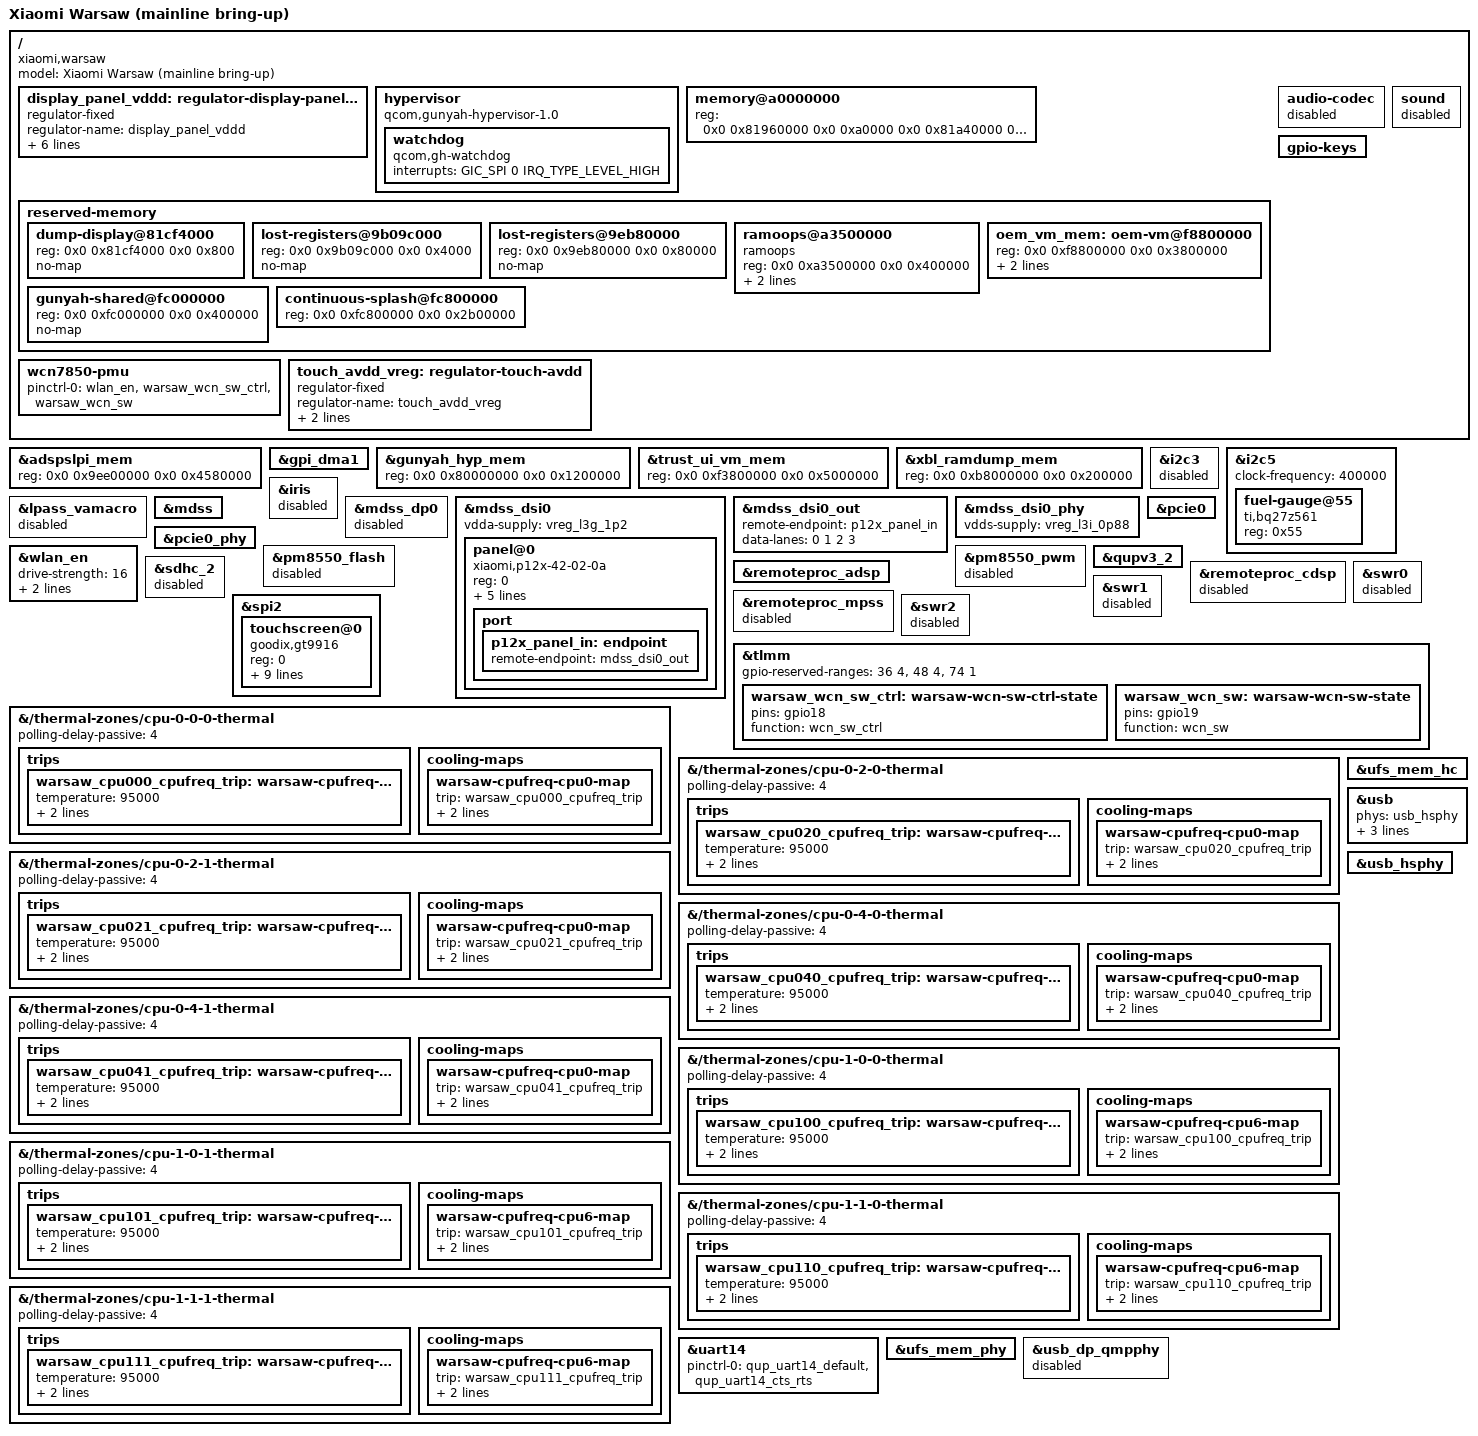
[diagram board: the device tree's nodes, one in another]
// SPDX-License-Identifier: BSD-3-Clause

#include "sm8750-mtp.dts"

/delete-node/ &cpusys_vm_mem;
/delete-node/ &oem_vm_mem;

/ {
	model = "Xiaomi Warsaw (mainline bring-up)";
	compatible = "xiaomi,warsaw", "qcom,sm8750";

	display_panel_vddd: regulator-display-panel-vddd {
		compatible = "regulator-fixed";
		regulator-name = "display_panel_vddd";
		regulator-min-microvolt = <1100000>;
		regulator-max-microvolt = <1100000>;
		gpio = <&tlmm 120 GPIO_ACTIVE_HIGH>;
		enable-active-high;
		regulator-always-on;
		regulator-boot-on;
	};

	hypervisor {
		compatible = "qcom,gunyah-hypervisor-1.0",
			     "qcom,gunyah-hypervisor", "simple-bus";
		#address-cells = <2>;
		#size-cells = <0>;

		watchdog {
			compatible = "qcom,gh-watchdog";
			interrupts = <GIC_SPI 0 IRQ_TYPE_LEVEL_HIGH>;
		};
	};

	memory@a0000000 {
		reg = <0x0 0x81960000 0x0 0xa0000
		       0x0 0x81a40000 0x0 0x1c0000
		       0x0 0x81cf4800 0x0 0xb800
		       0x0 0x82460000 0x0 0x40000
		       0x0 0xd8600000 0x0 0x0
		       0x0 0xe3720000 0x0 0x150e0000
		       0x0 0xfc400000 0x0 0x3400000
		       0x8 0x80000000 0x0 0x2f6fd000
		       0x8 0xb0000000 0x0 0x5500000
		       0xa 0x00000000 0x2 0x00000000
		       0x8 0xc0000000 0x1 0x40000000
		       0x8 0xb5700000 0x0 0x1e00000
		       0x0 0x82800000 0x0 0x2200000
		       0x0 0x89d80000 0x0 0x1c80000
		       0x0 0xa3380000 0x0 0x14c80000
		       0x0 0xb8200000 0x0 0x1cc23000
		       0x0 0xd5100000 0x0 0x2f00000>;
	};

	reserved-memory {
		dump-display@81cf4000 {
			reg = <0x0 0x81cf4000 0x0 0x800>;
			no-map;
		};

		lost-registers@9b09c000 {
			reg = <0x0 0x9b09c000 0x0 0x4000>;
			no-map;
		};

		lost-registers@9eb80000 {
			reg = <0x0 0x9eb80000 0x0 0x80000>;
			no-map;
		};

		ramoops@a3500000 {
			compatible = "ramoops";
			reg = <0x0 0xa3500000 0x0 0x400000>;
			console-size = <0x200000>;
			pmsg-size = <0x200000>;
		};

		oem_vm_mem: oem-vm@f8800000 {
			reg = <0x0 0xf8800000 0x0 0x3800000>;
			alignment = <0x0 0x400000>;
			no-map;
		};

		gunyah-shared@fc000000 {
			reg = <0x0 0xfc000000 0x0 0x400000>;
			no-map;
		};

		continuous-splash@fc800000 {
			reg = <0x0 0xfc800000 0x0 0x2b00000>;
		};
	};

	audio-codec {
		status = "disabled";
	};

	gpio-keys {
		status = "okay";
	};

	sound {
		status = "disabled";
	};

	wcn7850-pmu {
		pinctrl-0 = <&wlan_en>,
			    <&warsaw_wcn_sw_ctrl>,
			    <&warsaw_wcn_sw>;
	};

	touch_avdd_vreg: regulator-touch-avdd {
		compatible = "regulator-fixed";
		regulator-name = "touch_avdd_vreg";

		gpio = <&tlmm 114 GPIO_ACTIVE_HIGH>;
		enable-active-high;
	};
};

&adspslpi_mem {
	reg = <0x0 0x9ee00000 0x0 0x4580000>;
};

&gpi_dma1 {
	status = "okay";
};

&gunyah_hyp_mem {
	reg = <0x0 0x80000000 0x0 0x1200000>;
};

&trust_ui_vm_mem {
	reg = <0x0 0xf3800000 0x0 0x5000000>;
};

&xbl_ramdump_mem {
	reg = <0x0 0xb8000000 0x0 0x200000>;
};

&i2c3 {
	status = "disabled";
};

&i2c5 {
	clock-frequency = <400000>;
	status = "okay";

	fuel-gauge@55 {
		compatible = "ti,bq27z561";
		reg = <0x55>;
	};
};

&iris {
	status = "disabled";
};

&lpass_vamacro {
	status = "disabled";
};

&mdss {
	status = "okay";
};

&mdss_dp0 {
	status = "disabled";
};

&mdss_dsi0 {
	vdda-supply = <&vreg_l3g_1p2>;
	status = "okay";

	/delete-node/ panel@0;

	panel@0 {
		compatible = "xiaomi,p12x-42-02-0a";
		reg = <0>;

		vddio-supply = <&vreg_l2g_1p8>;
		vci-supply = <&vreg_l13b_3p0>;
		vdd-supply = <&display_panel_vddd>;

		pinctrl-0 = <&disp0_reset_n_active>, <&mdp_vsync>;
		pinctrl-1 = <&disp0_reset_n_suspend>, <&mdp_vsync>;
		pinctrl-names = "default", "sleep";

		port {
			p12x_panel_in: endpoint {
				remote-endpoint = <&mdss_dsi0_out>;
			};
		};
	};
};

&mdss_dsi0_out {
	remote-endpoint = <&p12x_panel_in>;
	data-lanes = <0 1 2 3>;
};

&mdss_dsi0_phy {
	vdds-supply = <&vreg_l3i_0p88>;
	status = "okay";
};

&pcie0 {
	status = "okay";
};

&pcie0_phy {
	status = "okay";
};

&wlan_en {
	/delete-property/ bias-pull-down;
	drive-strength = <16>;
	bias-pull-up;
	output-high;
};

&pm8550_flash {
	status = "disabled";
};

&pm8550_pwm {
	status = "disabled";
};

&qupv3_2 {
	status = "okay";
};

&remoteproc_adsp {
	status = "okay";
};

&remoteproc_cdsp {
	status = "disabled";
};

&remoteproc_mpss {
	status = "disabled";
};

&sdhc_2 {
	status = "disabled";
};

&spi2 {
	status = "okay";

	touchscreen@0 {
		compatible = "goodix,gt9916";
		reg = <0>;

		interrupt-parent = <&tlmm>;
		interrupts = <162 IRQ_TYPE_EDGE_FALLING>;

		reset-gpios = <&tlmm 161 GPIO_ACTIVE_LOW>;

		avdd-supply = <&touch_avdd_vreg>;
		vddio-supply = <&vreg_l12b_1p8>;

		goodix,coordinate-mode;

		spi-max-frequency = <15000000>;

		touchscreen-size-x = <1280>;
		touchscreen-size-y = <2772>;
	};
};

&swr0 {
	status = "disabled";
};

&swr1 {
	status = "disabled";
};

&swr2 {
	status = "disabled";
};

&tlmm {
	/* Keep firmware-reserved Warsaw GPIOs out of direct HLOS access. */
	gpio-reserved-ranges = <36 4>, <48 4>, <74 1>;

	warsaw_wcn_sw_ctrl: warsaw-wcn-sw-ctrl-state {
		pins = "gpio18";
		function = "wcn_sw_ctrl";
	};

	warsaw_wcn_sw: warsaw-wcn-sw-state {
		pins = "gpio19";
		function = "wcn_sw";
	};
};

&{/thermal-zones/cpu-0-0-0-thermal} {
	polling-delay-passive = <4>;

	trips {
		warsaw_cpu000_cpufreq_trip: warsaw-cpufreq-passive {
			temperature = <95000>;
			hysteresis = <8000>;
			type = "passive";
		};
	};

	cooling-maps {
		warsaw-cpufreq-cpu0-map {
			trip = <&warsaw_cpu000_cpufreq_trip>;
			cooling-device = <&cpu0 THERMAL_NO_LIMIT THERMAL_NO_LIMIT>;
		};
	};
};

&{/thermal-zones/cpu-0-2-0-thermal} {
	polling-delay-passive = <4>;

	trips {
		warsaw_cpu020_cpufreq_trip: warsaw-cpufreq-passive {
			temperature = <95000>;
			hysteresis = <8000>;
			type = "passive";
		};
	};

	cooling-maps {
		warsaw-cpufreq-cpu0-map {
			trip = <&warsaw_cpu020_cpufreq_trip>;
			cooling-device = <&cpu0 THERMAL_NO_LIMIT THERMAL_NO_LIMIT>;
		};
	};
};

&{/thermal-zones/cpu-0-2-1-thermal} {
	polling-delay-passive = <4>;

	trips {
		warsaw_cpu021_cpufreq_trip: warsaw-cpufreq-passive {
			temperature = <95000>;
			hysteresis = <8000>;
			type = "passive";
		};
	};

	cooling-maps {
		warsaw-cpufreq-cpu0-map {
			trip = <&warsaw_cpu021_cpufreq_trip>;
			cooling-device = <&cpu0 THERMAL_NO_LIMIT THERMAL_NO_LIMIT>;
		};
	};
};

&{/thermal-zones/cpu-0-4-0-thermal} {
	polling-delay-passive = <4>;

	trips {
		warsaw_cpu040_cpufreq_trip: warsaw-cpufreq-passive {
			temperature = <95000>;
			hysteresis = <8000>;
			type = "passive";
		};
	};

	cooling-maps {
		warsaw-cpufreq-cpu0-map {
			trip = <&warsaw_cpu040_cpufreq_trip>;
			cooling-device = <&cpu0 THERMAL_NO_LIMIT THERMAL_NO_LIMIT>;
		};
	};
};

&{/thermal-zones/cpu-0-4-1-thermal} {
	polling-delay-passive = <4>;

	trips {
		warsaw_cpu041_cpufreq_trip: warsaw-cpufreq-passive {
			temperature = <95000>;
			hysteresis = <8000>;
			type = "passive";
		};
	};

	cooling-maps {
		warsaw-cpufreq-cpu0-map {
			trip = <&warsaw_cpu041_cpufreq_trip>;
			cooling-device = <&cpu0 THERMAL_NO_LIMIT THERMAL_NO_LIMIT>;
		};
	};
};

&{/thermal-zones/cpu-1-0-0-thermal} {
	polling-delay-passive = <4>;

	trips {
		warsaw_cpu100_cpufreq_trip: warsaw-cpufreq-passive {
			temperature = <95000>;
			hysteresis = <8000>;
			type = "passive";
		};
	};

	cooling-maps {
		warsaw-cpufreq-cpu6-map {
			trip = <&warsaw_cpu100_cpufreq_trip>;
			cooling-device = <&cpu6 THERMAL_NO_LIMIT THERMAL_NO_LIMIT>;
		};
	};
};

&{/thermal-zones/cpu-1-0-1-thermal} {
	polling-delay-passive = <4>;

	trips {
		warsaw_cpu101_cpufreq_trip: warsaw-cpufreq-passive {
			temperature = <95000>;
			hysteresis = <8000>;
			type = "passive";
		};
	};

	cooling-maps {
		warsaw-cpufreq-cpu6-map {
			trip = <&warsaw_cpu101_cpufreq_trip>;
			cooling-device = <&cpu6 THERMAL_NO_LIMIT THERMAL_NO_LIMIT>;
		};
	};
};

&{/thermal-zones/cpu-1-1-0-thermal} {
	polling-delay-passive = <4>;

	trips {
		warsaw_cpu110_cpufreq_trip: warsaw-cpufreq-passive {
			temperature = <95000>;
			hysteresis = <8000>;
			type = "passive";
		};
	};

	cooling-maps {
		warsaw-cpufreq-cpu6-map {
			trip = <&warsaw_cpu110_cpufreq_trip>;
			cooling-device = <&cpu6 THERMAL_NO_LIMIT THERMAL_NO_LIMIT>;
		};
	};
};

&{/thermal-zones/cpu-1-1-1-thermal} {
	polling-delay-passive = <4>;

	trips {
		warsaw_cpu111_cpufreq_trip: warsaw-cpufreq-passive {
			temperature = <95000>;
			hysteresis = <8000>;
			type = "passive";
		};
	};

	cooling-maps {
		warsaw-cpufreq-cpu6-map {
			trip = <&warsaw_cpu111_cpufreq_trip>;
			cooling-device = <&cpu6 THERMAL_NO_LIMIT THERMAL_NO_LIMIT>;
		};
	};
};

&uart14 {
	pinctrl-0 = <&qup_uart14_default &qup_uart14_cts_rts>;
	status = "okay";
};

&ufs_mem_hc {
	status = "okay";
};

&ufs_mem_phy {
	status = "okay";
};

&usb {
	/delete-property/ phys;
	/delete-property/ phy-names;
	/delete-property/ usb-role-switch;

	phys = <&usb_hsphy>;
	phy-names = "usb2-phy";
	dr_mode = "peripheral";
	maximum-speed = "high-speed";
	qcom,select-utmi-as-pipe-clk;
	status = "okay";
};

&usb_dp_qmpphy {
	status = "disabled";
};

&usb_hsphy {
	status = "okay";
};
